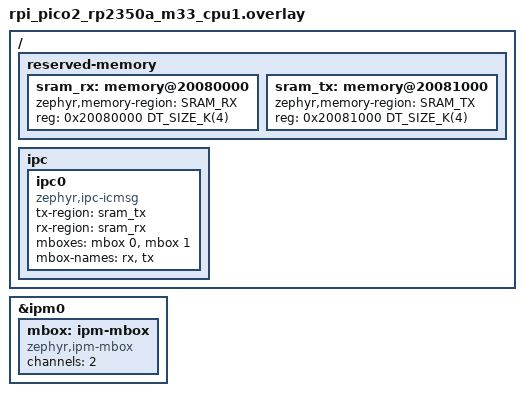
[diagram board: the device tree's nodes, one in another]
/*
 * Copyright (c) 2025 Dmitrii Sharshakov <d3dx12.xx@gmail.com>
 *
 * SPDX-License-Identifier: Apache-2.0
 */

/ {
	reserved-memory {
		/delete-node/ sram8;
		/delete-node/ sram9;

		sram_rx: memory@20080000 {
			zephyr,memory-region = "SRAM_RX";
			reg = <0x20080000 DT_SIZE_K(4)>;
		};

		sram_tx: memory@20081000 {
			zephyr,memory-region = "SRAM_TX";
			reg = <0x20081000 DT_SIZE_K(4)>;
		};
	};

	ipc {
		ipc0: ipc0 {
			compatible = "zephyr,ipc-icmsg";
			tx-region = <&sram_tx>;
			rx-region = <&sram_rx>;
			mboxes = <&mbox 0>, <&mbox 1>;
			mbox-names = "rx", "tx";
			status = "okay";
		};
	};
};

&ipm0 {
	mbox: ipm-mbox {
		compatible = "zephyr,ipm-mbox";
		#mbox-cells = <1>;
		channels = <2>;
		status = "okay";
	};
};
